# ESP32-P4 register map
Vendor: ESPRESSIF SYSTEMS (SHANGHAI) CO., LTD.; Series: ESP32 P-Series; File version: 3
CPU: RV32IMAFC r0p0, little endian, no MPU, FPU, 0 interrupt priority bits
Address unit: 32 bits
Registers are 32-bit, read-write, reset 0x0 unless marked. A register's access mark holds for its fields unless they carry their own. Offsets are from the block's base; [hi:lo] are bit positions; {n}, {i} and the like mark numbered series; <NAME> marks a mode.

## ISP (part 1 of 2) — ISP Peripheral
Base 0x500A1000
0x00 VER_DATE reset 0x20210608 — version control register
  [31:0] VER_DATA — csv version
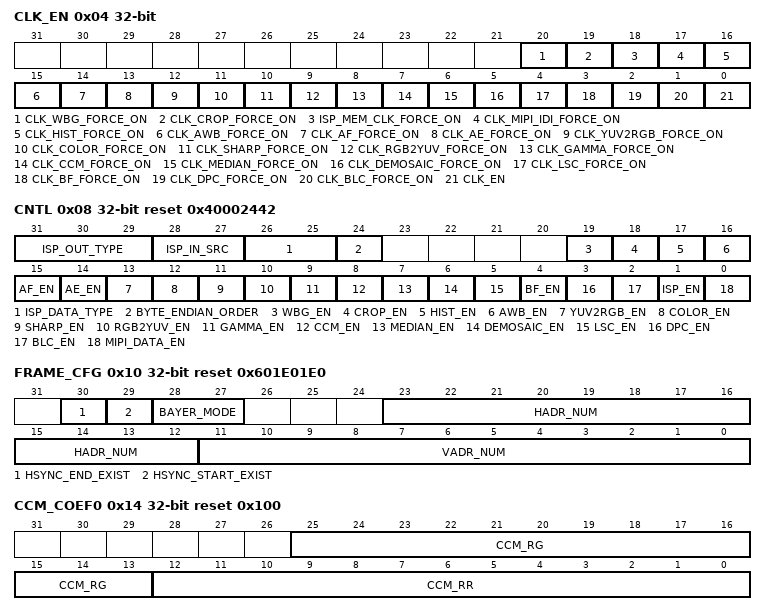
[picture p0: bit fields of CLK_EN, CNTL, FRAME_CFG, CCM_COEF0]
0x04 CLK_EN — isp clk control register
  [20] CLK_WBG_FORCE_ON — this bit configures the clk force on of wbg. 0: disable, 1: enable
  [19] CLK_CROP_FORCE_ON — this bit configures the clk force on of crop. 0: disable, 1: enable
  [18] ISP_MEM_CLK_FORCE_ON — this bit configures the clk force on of all isp memory. 0: disable, 1: enable
  [17] CLK_MIPI_IDI_FORCE_ON — this bit configures the clk force on of mipi idi input. 0: disable, 1: enable
  [16] CLK_HIST_FORCE_ON — this bit configures the clk force on of hist. 0: disable, 1: enable
  [15] CLK_AWB_FORCE_ON — this bit configures the clk force on of awb. 0: disable, 1: enable
  [14] CLK_AF_FORCE_ON — this bit configures the clk force on of af. 0: disable, 1: enable
  [13] CLK_AE_FORCE_ON — this bit configures the clk force on of ae. 0: disable, 1: enable
  [12] CLK_YUV2RGB_FORCE_ON — this bit configures the clk force on of yuv2rgb. 0: disable, 1: enable
  [11] CLK_COLOR_FORCE_ON — this bit configures the clk force on of color. 0: disable, 1: enable
  [10] CLK_SHARP_FORCE_ON — this bit configures the clk force on of sharp. 0: disable, 1: enable
  [9] CLK_RGB2YUV_FORCE_ON — this bit configures the clk force on of rgb2yuv. 0: disable, 1: enable
  [8] CLK_GAMMA_FORCE_ON — this bit configures the clk force on of gamma. 0: disable, 1: enable
  [7] CLK_CCM_FORCE_ON — this bit configures the clk force on of ccm. 0: disable, 1: enable
  [6] CLK_MEDIAN_FORCE_ON — this bit configures the clk force on of median. 0: disable, 1: enable
  [5] CLK_DEMOSAIC_FORCE_ON — this bit configures the clk force on of demosaic. 0: disable, 1: enable
  [4] CLK_LSC_FORCE_ON — this bit configures the clk force on of lsc. 0: disable, 1: enable
  [3] CLK_BF_FORCE_ON — this bit configures the clk force on of bf. 0: disable, 1: enable
  [2] CLK_DPC_FORCE_ON — this bit configures the clk force on of dpc. 0: disable, 1: enable
  [1] CLK_BLC_FORCE_ON — this bit configures the clk force on of blc. 0: disable, 1: enable
  [0] CLK_EN — this bit configures the clk force on of isp reg. 0: disable, 1: enable
0x08 CNTL reset 0x40002442 — isp module enable control register
  [31:29] ISP_OUT_TYPE — this field configures pixel output type, 0: RAW8 1: YUV422 2: RGB888 3: YUV420 4: RGB565
  [28:27] ISP_IN_SRC — this field configures input data source, 0:CSI HOST 1:CAM 2:DMA
  [26:25] ISP_DATA_TYPE — this field configures input data type, 0:RAW8 1:RAW10 2:RAW12
  [24] BYTE_ENDIAN_ORDER — select input idi data byte_endian_order when isp is bypass, 0: csi_data[31:0], 1: {[7:0], [15:8], [23:16], [31:24]}
  [19] WBG_EN — this bit configures wbg enable. 0: disable, 1: enable
  [18] CROP_EN — this bit configures crop enable. 0: disable, 1: enable
  [17] HIST_EN — this bit configures hist enable. 0: disable, 1: enable
  [16] AWB_EN — this bit configures awb enable. 0: disable, 1: enable
  [15] AF_EN — this bit configures af enable. 0: disable, 1: enable
  [14] AE_EN — this bit configures ae enable. 0: disable, 1: enable
  [13] YUV2RGB_EN — this bit configures yuv2rgb enable. 0: disable, 1: enable
  [12] COLOR_EN — this bit configures color enable. 0: disable, 1: enable
  [11] SHARP_EN — this bit configures sharp enable. 0: disable, 1: enable
  [10] RGB2YUV_EN — this bit configures rgb2yuv enable. 0: disable, 1: enable
  [9] GAMMA_EN — this bit configures gamma enable. 0: disable, 1: enable
  [8] CCM_EN — this bit configures ccm enable. 0: disable, 1: enable
  [7] MEDIAN_EN — this bit configures median enable. 0: disable, 1: enable
  [6] DEMOSAIC_EN — this bit configures demosaic enable. 0: disable, 1: enable
  [5] LSC_EN — this bit configures lsc enable. 0: disable, 1: enable
  [4] BF_EN — this bit configures bf enable. 0: disable, 1: enable
  [3] DPC_EN — this bit configures dpc enable. 0: disable, 1: enable
  [2] BLC_EN — this bit configures blc enable. 0: disable, 1: enable
  [1] ISP_EN — this bit configures isp global enable. 0: disable, 1: enable
  [0] MIPI_DATA_EN — this bit configures mipi input data enable. 0: disable, 1: enable
0x0C HSYNC_CNT reset 0x7 — header hsync interval control register
  [7:0] HSYNC_CNT — this field configures the number of clock before hsync and after vsync and line_end when decodes pix data from idi to isp
0x10 FRAME_CFG reset 0x601E01E0 — frame control parameter register
  [30] HSYNC_END_EXIST — this bit configures the line start packet exist or not. 0: not exist, 1: exist
  [29] HSYNC_START_EXIST — this bit configures the line end packet exist or not. 0: not exist, 1: exist
  [28:27] BAYER_MODE — this field configures the bayer mode of input pixel. 00 : BG/GR 01 : GB/RG 10 : GR/BG 11 : RG/GB
  [23:12] HADR_NUM — this field configures input image size in x-direction, image line number - 1
  [11:0] VADR_NUM — this field configures input image size in y-direction, image row number - 1
0x14 CCM_COEF0 reset 0x100 — ccm coef register 0
  [25:13] CCM_RG — this field configures the color correction matrix coefficient
  [12:0] CCM_RR — this field configures the color correction matrix coefficient
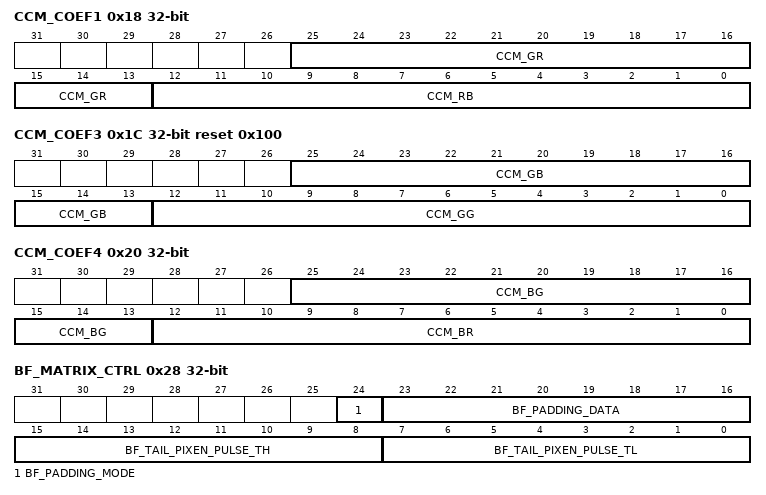
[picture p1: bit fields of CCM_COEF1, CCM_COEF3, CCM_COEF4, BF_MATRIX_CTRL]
0x18 CCM_COEF1 — ccm coef register 1
  [25:13] CCM_GR — this field configures the color correction matrix coefficient
  [12:0] CCM_RB — this field configures the color correction matrix coefficient
0x1C CCM_COEF3 reset 0x100 — ccm coef register 3
  [25:13] CCM_GB — this field configures the color correction matrix coefficient
  [12:0] CCM_GG — this field configures the color correction matrix coefficient
0x20 CCM_COEF4 — ccm coef register 4
  [25:13] CCM_BG — this field configures the color correction matrix coefficient
  [12:0] CCM_BR — this field configures the color correction matrix coefficient
0x24 CCM_COEF5 reset 0x100 — ccm coef register 5
  [12:0] CCM_BB — this field configures the color correction matrix coefficient
0x28 BF_MATRIX_CTRL — bf pix2matrix ctrl
  [24] BF_PADDING_MODE — this bit configures the padding mode of bf matrix. 0: use pixel in image to do padding 1: use reg_padding_data to do padding
  [23:16] BF_PADDING_DATA — this field configures bf matrix padding data
  [15:8] BF_TAIL_PIXEN_PULSE_TH — matrix tail pixen high level threshold, must < hnum-1, only reg_bf_tail_pixen_pulse_th!=0 and reg_bf_tail_pixen_pulse_tl!=0 and reg_bf_tail_pixen_pulse_th < reg_bf_tail_pixen_pulse_tl will enable tail pulse function
  [7:0] BF_TAIL_PIXEN_PULSE_TL — matrix tail pixen low level threshold, should not to large to prevent expanding to next frame, only reg_bf_tail_pixen_pulse_th!=0 and reg_bf_tail_pixen_pulse_tl!=0 and reg_bf_tail_pixen_pulse_th < reg_bf_tail_pixen_pulse_tl will enable tail pulse function
0x2C BF_SIGMA reset 0x2 — bf denoising level control register
  [5:0] SIGMA — this field configures the bayer denoising level, valid data from 2 to 20
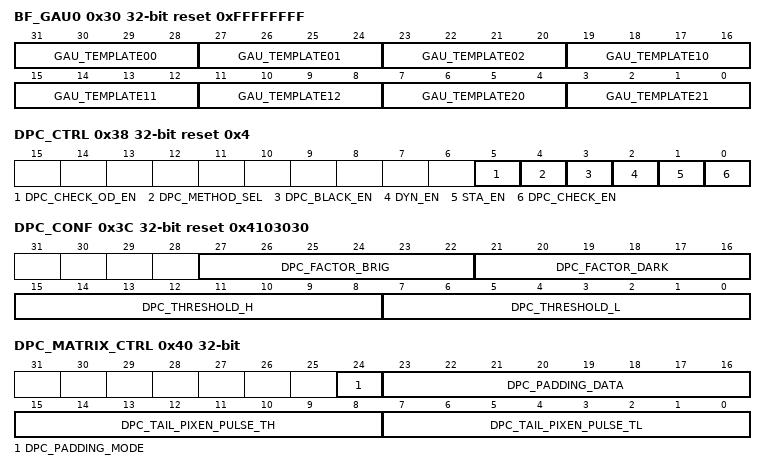
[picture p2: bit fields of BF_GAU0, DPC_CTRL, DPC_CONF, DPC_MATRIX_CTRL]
0x30 BF_GAU0 reset 0xFFFFFFFF — bf gau template register 0
  [31:28] GAU_TEMPLATE00 — this field configures index 00 of gausian template
  [27:24] GAU_TEMPLATE01 — this field configures index 01 of gausian template
  [23:20] GAU_TEMPLATE02 — this field configures index 02 of gausian template
  [19:16] GAU_TEMPLATE10 — this field configures index 10 of gausian template
  [15:12] GAU_TEMPLATE11 — this field configures index 11 of gausian template
  [11:8] GAU_TEMPLATE12 — this field configures index 12 of gausian template
  [7:4] GAU_TEMPLATE20 — this field configures index 20 of gausian template
  [3:0] GAU_TEMPLATE21 — this field configures index 21 of gausian template
0x34 BF_GAU1 reset 0xF — bf gau template register 1
  [3:0] GAU_TEMPLATE22 — this field configures index 22 of gausian template
0x38 DPC_CTRL reset 0x4 — DPC mode control register
  [5] DPC_CHECK_OD_EN — this bit configures output pixel data when in check mode or not. 0: no data output, 1: data output
  [4] DPC_METHOD_SEL — this bit configures dyn dpc method select. 0: simple method, 1: hard method
  [3] DPC_BLACK_EN — this bit configures input image type select when in check mode, 0: white img, 1: black img
  [2] DYN_EN — this bit configures the dyn dpc enable. 0: disable, 1: enable
  [1] STA_EN — this bit configures the sta dpc enable. 0: disable, 1: enable
  [0] DPC_CHECK_EN — this bit configures the check mode enable. 0: disable, 1: enable
0x3C DPC_CONF reset 0x4103030 — DPC parameter config register
  [27:22] DPC_FACTOR_BRIG — this field configures the dynamic correction method 1 bright factor
  [21:16] DPC_FACTOR_DARK — this field configures the dynamic correction method 1 dark factor
  [15:8] DPC_THRESHOLD_H — this bit configures the threshold to detect white img in check mode, or the high threshold(use 8 bit 0~255) in dyn method 0, or the high threshold factor (use 5 bit 10000-> 16/16, 00001->1/16, 0/16~16/16) in dyn method 1
  [7:0] DPC_THRESHOLD_L — this bit configures the threshold to detect black img in check mode, or the low threshold(use 8 bit 0~255) in dyn method 0, or the low threshold factor (use 5 bit 10000-> 16/16, 00001->1/16, 0/16~16/16) in dyn method 1
0x40 DPC_MATRIX_CTRL — dpc pix2matrix ctrl
  [24] DPC_PADDING_MODE — this bit configures the padding mode of dpc matrix. 0: use pixel in image to do padding 1: use reg_padding_data to do padding
  [23:16] DPC_PADDING_DATA — this field configures dpc matrix padding data
  [15:8] DPC_TAIL_PIXEN_PULSE_TH — matrix tail pixen high level threshold, must < hnum-1, only reg_dpc_tail_pixen_pulse_th!=0 and reg_dpc_tail_pixen_pulse_tl!=0 and reg_dpc_tail_pixen_pulse_th < reg_dpc_tail_pixen_pulse_tl will enable tail pulse function
  [7:0] DPC_TAIL_PIXEN_PULSE_TL — matrix tail pixen low level threshold, should not to large to prevent expanding to next frame, only reg_dpc_tail_pixen_pulse_th!=0 and reg_dpc_tail_pixen_pulse_tl!=0 and reg_dpc_tail_pixen_pulse_th < reg_dpc_tail_pixen_pulse_tl will enable tail pulse function
0x44 DPC_DEADPIX_CNT ro — DPC dead-pix number register
  [9:0] DPC_DEADPIX_CNT — this field represents the dead pixel count
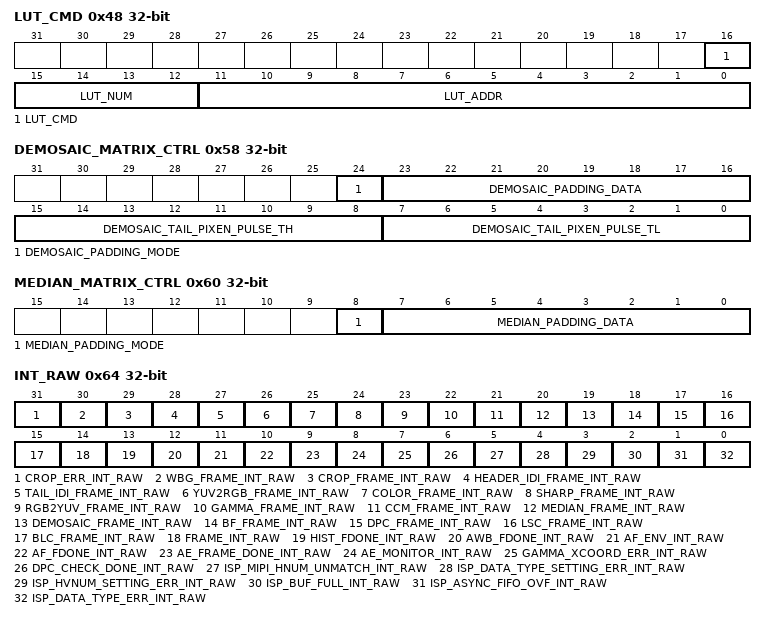
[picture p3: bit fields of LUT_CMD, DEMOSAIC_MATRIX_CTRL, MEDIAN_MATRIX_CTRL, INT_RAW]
0x48 LUT_CMD wo — LUT command register
  [16] LUT_CMD — this bit configures the access event of lut. 0:rd 1: wr
  [15:12] LUT_NUM — this field configures the lut selection. 0000:LSC LUT. 0001:DPC LUT. 0010:AWB LUT
  [11:0] LUT_ADDR — this field configures the lut access addr, when select lsc lut, [11:10]:00 sel gb_b lut, 01 sel r_gr lut
0x4C LUT_WDATA — LUT write data register
  [31:0] LUT_WDATA — this field configures the write data of lut. please initial ISP_LUT_WDATA before write ISP_LUT_CMD register
0x50 LUT_RDATA ro — LUT read data register
  [31:0] LUT_RDATA — this field represents the read data of lut. read ISP_LUT_RDATA after write ISP_LUT_CMD register
0x54 LSC_TABLESIZE reset 0x1F — LSC point in x-direction
  [4:0] LSC_XTABLESIZE — this field configures lsc table size in x-direction
0x58 DEMOSAIC_MATRIX_CTRL — demosaic pix2matrix ctrl
  [24] DEMOSAIC_PADDING_MODE — this bit configures the padding mode of demosaic matrix. 0: use pixel in image to do padding 1: use reg_padding_data to do padding
  [23:16] DEMOSAIC_PADDING_DATA — this field configures demosaic matrix padding data
  [15:8] DEMOSAIC_TAIL_PIXEN_PULSE_TH — matrix tail pixen high level threshold, must < hnum-1, only reg_demosaic_tail_pixen_pulse_th!=0 and reg_demosaic_tail_pixen_pulse_tl!=0 and reg_demosaic_tail_pixen_pulse_th < reg_demosaic_tail_pixen_pulse_tl will enable tail pulse function
  [7:0] DEMOSAIC_TAIL_PIXEN_PULSE_TL — matrix tail pixen low level threshold, should not to large to prevent expanding to next frame, only reg_demosaic_tail_pixen_pulse_th!=0 and reg_demosaic_tail_pixen_pulse_tl!=0 and reg_demosaic_tail_pixen_pulse_th < reg_demosaic_tail_pixen_pulse_tl will enable tail pulse function
0x5C DEMOSAIC_GRAD_RATIO reset 0x10 — demosaic gradient select ratio
  [5:0] DEMOSAIC_GRAD_RATIO — this field configures demosaic gradient select ratio
0x60 MEDIAN_MATRIX_CTRL — median pix2matrix ctrl
  [8] MEDIAN_PADDING_MODE — this bit configures the padding mode of median matrix. 0: use pixel in image to do padding 1: use reg_padding_data to do padding
  [7:0] MEDIAN_PADDING_DATA — this field configures median matrix padding data
0x64 INT_RAW ro — raw interrupt register
  [31] CROP_ERR_INT_RAW — the raw interrupt status of crop error
  [30] WBG_FRAME_INT_RAW — the raw interrupt status of wbg frame done
  [29] CROP_FRAME_INT_RAW — the raw interrupt status of crop frame done
  [28] HEADER_IDI_FRAME_INT_RAW — the raw interrupt status of real input frame end of isp_input
  [27] TAIL_IDI_FRAME_INT_RAW — the raw interrupt status of isp_tail idi frame_end
  [26] YUV2RGB_FRAME_INT_RAW — the raw interrupt status of yuv2rgb frame done
  [25] COLOR_FRAME_INT_RAW — the raw interrupt status of color frame done
  [24] SHARP_FRAME_INT_RAW — the raw interrupt status of sharp frame done
  [23] RGB2YUV_FRAME_INT_RAW — the raw interrupt status of rgb2yuv frame done
  [22] GAMMA_FRAME_INT_RAW — the raw interrupt status of gamma frame done
  [21] CCM_FRAME_INT_RAW — the raw interrupt status of ccm frame done
  [20] MEDIAN_FRAME_INT_RAW — the raw interrupt status of median frame done
  [19] DEMOSAIC_FRAME_INT_RAW — the raw interrupt status of demosaic frame done
  [18] BF_FRAME_INT_RAW — the raw interrupt status of bf frame done
  [17] DPC_FRAME_INT_RAW — the raw interrupt status of dpc frame done
  [16] LSC_FRAME_INT_RAW — the raw interrupt status of lsc frame done
  [15] BLC_FRAME_INT_RAW — the raw interrupt status of blc frame done
  [14] FRAME_INT_RAW — the raw interrupt status of isp frame end
  [13] HIST_FDONE_INT_RAW — the raw interrupt status of histogram. send a int pulse when statistic of one frame histogram done
  [12] AWB_FDONE_INT_RAW — the raw interrupt status of awb. send a int pulse when statistic of one awb frame done
  [11] AF_ENV_INT_RAW — the raw interrupt status of af monitor. send a int pulse when env_det function enabled and environment changes detected
  [10] AF_FDONE_INT_RAW — the raw interrupt status of af statistic. when auto_update enable, each frame done will send one int pulse when manual_update, each time when write 1 to reg_manual_update will send a int pulse when next frame done
  [9] AE_FRAME_DONE_INT_RAW — the raw interrupt status of ae.
  [8] AE_MONITOR_INT_RAW — the raw interrupt status of ae monitor
  [7] GAMMA_XCOORD_ERR_INT_RAW — the raw interrupt status of gamma setting error. it report the sum of the lengths represented by reg_gamma_x00~x0F isn't equal to 256
  [6] DPC_CHECK_DONE_INT_RAW — the raw interrupt status of dpc check done
  [5] ISP_MIPI_HNUM_UNMATCH_INT_RAW — the raw interrupt status of hnum setting unmatch with mipi input
  [4] ISP_DATA_TYPE_SETTING_ERR_INT_RAW — the raw interrupt status of setting invalid reg_data_type
  [3] ISP_HVNUM_SETTING_ERR_INT_RAW — the raw interrupt status of hnum and vnum setting format error
  [2] ISP_BUF_FULL_INT_RAW — the raw interrupt status of isp input buffer full
  [1] ISP_ASYNC_FIFO_OVF_INT_RAW — the raw interrupt status of isp input fifo overflow
  [0] ISP_DATA_TYPE_ERR_INT_RAW — the raw interrupt status of input data type error. isp only support RGB bayer data type, other type will report type_err_int
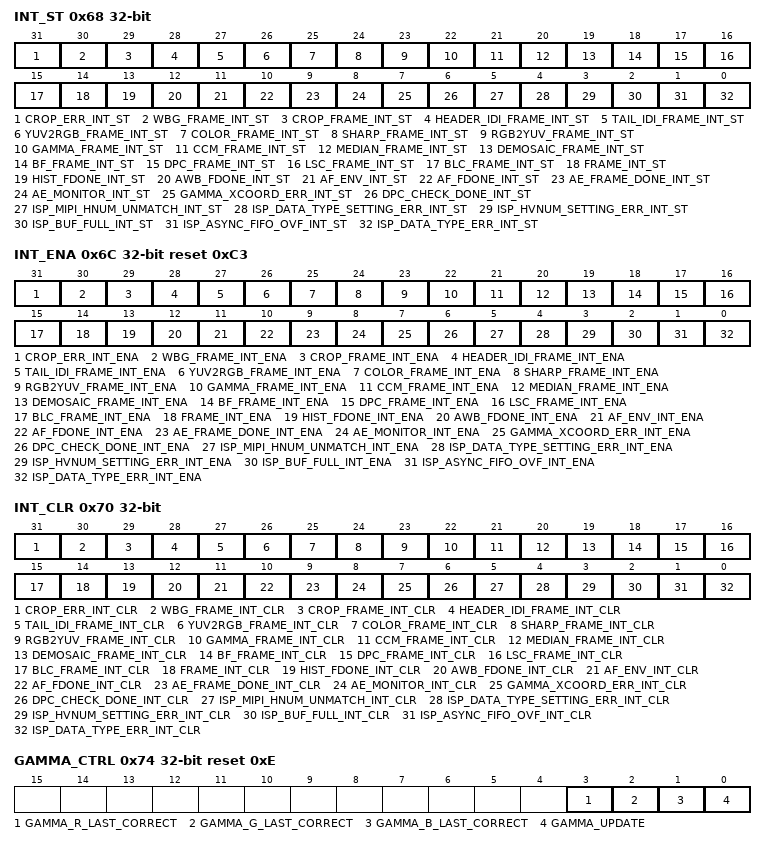
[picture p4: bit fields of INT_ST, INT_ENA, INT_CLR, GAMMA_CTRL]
0x68 INT_ST ro — masked interrupt register
  [31] CROP_ERR_INT_ST — the masked interrupt status of crop error
  [30] WBG_FRAME_INT_ST — the masked interrupt status of wbg frame done
  [29] CROP_FRAME_INT_ST — the masked interrupt status of crop frame done
  [28] HEADER_IDI_FRAME_INT_ST — the masked interrupt status of real input frame end of isp_input
  [27] TAIL_IDI_FRAME_INT_ST — the masked interrupt status of isp_tail idi frame_end
  [26] YUV2RGB_FRAME_INT_ST — the masked interrupt status of yuv2rgb frame done
  [25] COLOR_FRAME_INT_ST — the masked interrupt status of color frame done
  [24] SHARP_FRAME_INT_ST — the masked interrupt status of sharp frame done
  [23] RGB2YUV_FRAME_INT_ST — the masked interrupt status of rgb2yuv frame done
  [22] GAMMA_FRAME_INT_ST — the masked interrupt status of gamma frame done
  [21] CCM_FRAME_INT_ST — the masked interrupt status of ccm frame done
  [20] MEDIAN_FRAME_INT_ST — the masked interrupt status of median frame done
  [19] DEMOSAIC_FRAME_INT_ST — the masked interrupt status of demosaic frame done
  [18] BF_FRAME_INT_ST — the masked interrupt status of bf frame done
  [17] DPC_FRAME_INT_ST — the masked interrupt status of dpc frame done
  [16] LSC_FRAME_INT_ST — the masked interrupt status of lsc frame done
  [15] BLC_FRAME_INT_ST — the masked interrupt status of blc frame done
  [14] FRAME_INT_ST — the masked interrupt status of isp frame end
  [13] HIST_FDONE_INT_ST — the masked interrupt status of histogram
  [12] AWB_FDONE_INT_ST — the masked interrupt status of awb
  [11] AF_ENV_INT_ST — the masked interrupt status of af monitor
  [10] AF_FDONE_INT_ST — the masked interrupt status of af statistic
  [9] AE_FRAME_DONE_INT_ST — the masked interrupt status of ae
  [8] AE_MONITOR_INT_ST — the masked interrupt status of ae monitor
  [7] GAMMA_XCOORD_ERR_INT_ST — the masked interrupt status of gamma setting error
  [6] DPC_CHECK_DONE_INT_ST — the masked interrupt status of dpc check done
  [5] ISP_MIPI_HNUM_UNMATCH_INT_ST — the masked interrupt status of hnum setting unmatch with mipi input
  [4] ISP_DATA_TYPE_SETTING_ERR_INT_ST — the masked interrupt status of setting invalid reg_data_type
  [3] ISP_HVNUM_SETTING_ERR_INT_ST — the masked interrupt status of hnum and vnum setting format error
  [2] ISP_BUF_FULL_INT_ST — the masked interrupt status of isp input buffer full
  [1] ISP_ASYNC_FIFO_OVF_INT_ST — the masked interrupt status of isp input fifo overflow
  [0] ISP_DATA_TYPE_ERR_INT_ST — the masked interrupt status of input data type error
0x6C INT_ENA reset 0xC3 — interrupt enable register
  [31] CROP_ERR_INT_ENA — write 1 to enable crop error
  [30] WBG_FRAME_INT_ENA — write 1 to enable wbg frame done
  [29] CROP_FRAME_INT_ENA — write 1 to enable crop frame done
  [28] HEADER_IDI_FRAME_INT_ENA — write 1 to enable real input frame end of isp_input
  [27] TAIL_IDI_FRAME_INT_ENA — write 1 to enable isp_tail idi frame_end
  [26] YUV2RGB_FRAME_INT_ENA — write 1 to enable yuv2rgb frame done
  [25] COLOR_FRAME_INT_ENA — write 1 to enable color frame done
  [24] SHARP_FRAME_INT_ENA — write 1 to enable sharp frame done
  [23] RGB2YUV_FRAME_INT_ENA — write 1 to enable rgb2yuv frame done
  [22] GAMMA_FRAME_INT_ENA — write 1 to enable gamma frame done
  [21] CCM_FRAME_INT_ENA — write 1 to enable ccm frame done
  [20] MEDIAN_FRAME_INT_ENA — write 1 to enable median frame done
  [19] DEMOSAIC_FRAME_INT_ENA — write 1 to enable demosaic frame done
  [18] BF_FRAME_INT_ENA — write 1 to enable bf frame done
  [17] DPC_FRAME_INT_ENA — write 1 to enable dpc frame done
  [16] LSC_FRAME_INT_ENA — write 1 to enable lsc frame done
  [15] BLC_FRAME_INT_ENA — write 1 to enable blc frame done
  [14] FRAME_INT_ENA — write 1 to enable isp frame end
  [13] HIST_FDONE_INT_ENA — write 1 to enable histogram
  [12] AWB_FDONE_INT_ENA — write 1 to enable awb
  [11] AF_ENV_INT_ENA — write 1 to enable af monitor
  [10] AF_FDONE_INT_ENA — write 1 to enable af statistic
  [9] AE_FRAME_DONE_INT_ENA — write 1 to enable ae
  [8] AE_MONITOR_INT_ENA — write 1 to enable ae monitor
  [7] GAMMA_XCOORD_ERR_INT_ENA — write 1 to enable gamma setting error
  [6] DPC_CHECK_DONE_INT_ENA — write 1 to enable dpc check done
  [5] ISP_MIPI_HNUM_UNMATCH_INT_ENA — write 1 to enable hnum setting unmatch with mipi input
  [4] ISP_DATA_TYPE_SETTING_ERR_INT_ENA — write 1 to enable setting invalid reg_data_type
  [3] ISP_HVNUM_SETTING_ERR_INT_ENA — write 1 to enable hnum and vnum setting format error
  [2] ISP_BUF_FULL_INT_ENA — write 1 to enable isp input buffer full
  [1] ISP_ASYNC_FIFO_OVF_INT_ENA — write 1 to enable isp input fifo overflow
  [0] ISP_DATA_TYPE_ERR_INT_ENA — write 1 to enable input data type error
0x70 INT_CLR wo — interrupt clear register
  [31] CROP_ERR_INT_CLR — write 1 to clear crop error
  [30] WBG_FRAME_INT_CLR — write 1 to clear wbg frame done
  [29] CROP_FRAME_INT_CLR — write 1 to clear crop frame done
  [28] HEADER_IDI_FRAME_INT_CLR — write 1 to clear real input frame end of isp_input
  [27] TAIL_IDI_FRAME_INT_CLR — write 1 to clear isp_tail idi frame_end
  [26] YUV2RGB_FRAME_INT_CLR — write 1 to clear yuv2rgb frame done
  [25] COLOR_FRAME_INT_CLR — write 1 to clear color frame done
  [24] SHARP_FRAME_INT_CLR — write 1 to clear sharp frame done
  [23] RGB2YUV_FRAME_INT_CLR — write 1 to clear rgb2yuv frame done
  [22] GAMMA_FRAME_INT_CLR — write 1 to clear gamma frame done
  [21] CCM_FRAME_INT_CLR — write 1 to clear ccm frame done
  [20] MEDIAN_FRAME_INT_CLR — write 1 to clear median frame done
  [19] DEMOSAIC_FRAME_INT_CLR — write 1 to clear demosaic frame done
  [18] BF_FRAME_INT_CLR — write 1 to clear bf frame done
  [17] DPC_FRAME_INT_CLR — write 1 to clear dpc frame done
  [16] LSC_FRAME_INT_CLR — write 1 to clear lsc frame done
  [15] BLC_FRAME_INT_CLR — write 1 to clear blc frame done
  [14] FRAME_INT_CLR — write 1 to clear isp frame end
  [13] HIST_FDONE_INT_CLR — write 1 to clear histogram
  [12] AWB_FDONE_INT_CLR — write 1 to clear awb
  [11] AF_ENV_INT_CLR — write 1 to clear af monitor
  [10] AF_FDONE_INT_CLR — write 1 to clear af statistic
  [9] AE_FRAME_DONE_INT_CLR — write 1 to clear ae
  [8] AE_MONITOR_INT_CLR — write 1 to clear ae monitor
  [7] GAMMA_XCOORD_ERR_INT_CLR — write 1 to clear gamma setting error
  [6] DPC_CHECK_DONE_INT_CLR — write 1 to clear dpc check done
  [5] ISP_MIPI_HNUM_UNMATCH_INT_CLR — write 1 to clear hnum setting unmatch with mipi input
  [4] ISP_DATA_TYPE_SETTING_ERR_INT_CLR — write 1 to clear setting invalid reg_data_type
  [3] ISP_HVNUM_SETTING_ERR_INT_CLR — write 1 to clear hnum and vnum setting format error
  [2] ISP_BUF_FULL_INT_CLR — write 1 to clear isp input buffer full
  [1] ISP_ASYNC_FIFO_OVF_INT_CLR — write 1 to clear isp input fifo overflow
  [0] ISP_DATA_TYPE_ERR_INT_CLR — write 1 to clear input data type error
0x74 GAMMA_CTRL reset 0xE — gamma control register
  [3] GAMMA_R_LAST_CORRECT — this bit configures enable of last r segment correcction. 0: disable, 1: enable
  [2] GAMMA_G_LAST_CORRECT — this bit configures enable of last g segment correcction. 0: disable, 1: enable
  [1] GAMMA_B_LAST_CORRECT — this bit configures enable of last b segment correcction. 0: disable, 1: enable
  [0] GAMMA_UPDATE — Indicates that gamma register configuration is complete
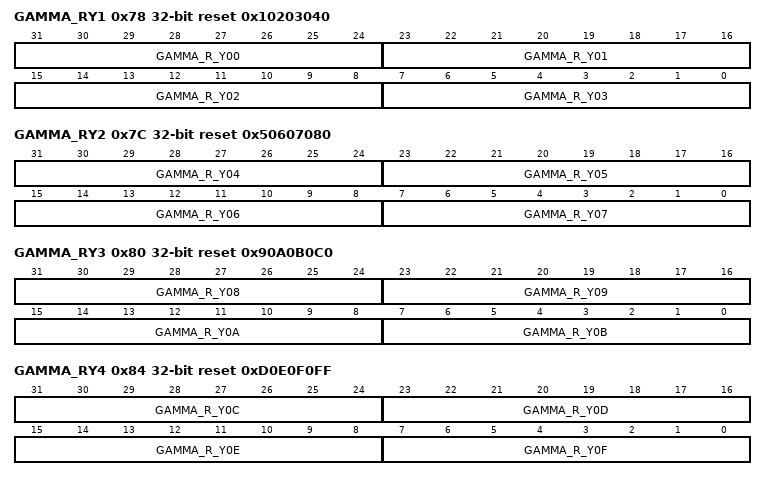
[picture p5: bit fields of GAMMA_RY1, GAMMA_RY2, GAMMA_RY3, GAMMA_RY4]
0x78 GAMMA_RY1 reset 0x10203040 — point of Y-axis of r channel gamma curve register 1
  [31-8n:24-8n] GAMMA_R_Y{n:02} (n=0..3) — this field configures the point {n} of Y-axis of r channel gamma curve
0x7C GAMMA_RY2 reset 0x50607080 — point of Y-axis of r channel gamma curve register 2
  [63-8n:56-8n] GAMMA_R_Y{n:02} (n=4..7) — this field configures the point {n} of Y-axis of r channel gamma curve
0x80 GAMMA_RY3 reset 0x90A0B0C0 — point of Y-axis of r channel gamma curve register 3
  [31:24] GAMMA_R_Y08 — this field configures the point 8 of Y-axis of r channel gamma curve
  [23:16] GAMMA_R_Y09 — this field configures the point 9 of Y-axis of r channel gamma curve
  [15:8] GAMMA_R_Y0A — this field configures the point 10 of Y-axis of r channel gamma curve
  [7:0] GAMMA_R_Y0B — this field configures the point 11 of Y-axis of r channel gamma curve
0x84 GAMMA_RY4 reset 0xD0E0F0FF — point of Y-axis of r channel gamma curve register 4
  [31:24] GAMMA_R_Y0C — this field configures the point 12 of Y-axis of r channel gamma curve
  [23:16] GAMMA_R_Y0D — this field configures the point 13 of Y-axis of r channel gamma curve
  [15:8] GAMMA_R_Y0E — this field configures the point 14 of Y-axis of r channel gamma curve
  [7:0] GAMMA_R_Y0F — this field configures the point 15 of Y-axis of r channel gamma curve
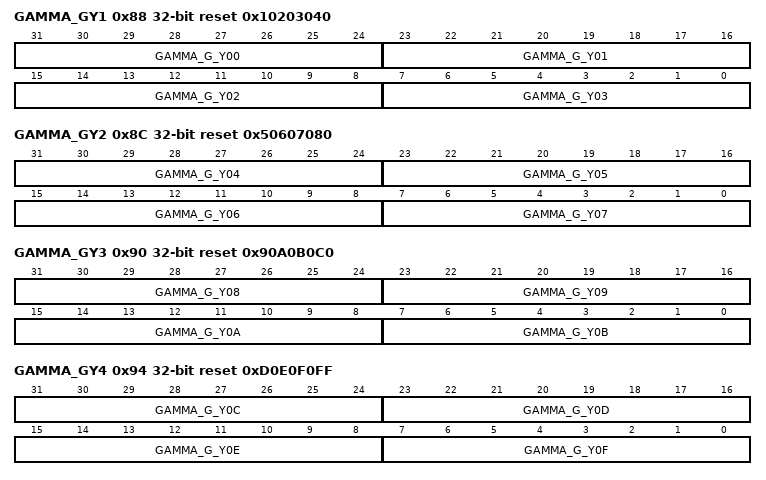
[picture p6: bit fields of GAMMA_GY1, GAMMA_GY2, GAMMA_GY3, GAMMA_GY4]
0x88 GAMMA_GY1 reset 0x10203040 — point of Y-axis of g channel gamma curve register 1
  [31-8n:24-8n] GAMMA_G_Y{n:02} (n=0..3) — this field configures the point {n} of Y-axis of g channel gamma curve
0x8C GAMMA_GY2 reset 0x50607080 — point of Y-axis of g channel gamma curve register 2
  [63-8n:56-8n] GAMMA_G_Y{n:02} (n=4..7) — this field configures the point {n} of Y-axis of g channel gamma curve
0x90 GAMMA_GY3 reset 0x90A0B0C0 — point of Y-axis of g channel gamma curve register 3
  [31:24] GAMMA_G_Y08 — this field configures the point 8 of Y-axis of g channel gamma curve
  [23:16] GAMMA_G_Y09 — this field configures the point 9 of Y-axis of g channel gamma curve
  [15:8] GAMMA_G_Y0A — this field configures the point 10 of Y-axis of g channel gamma curve
  [7:0] GAMMA_G_Y0B — this field configures the point 11 of Y-axis of g channel gamma curve
0x94 GAMMA_GY4 reset 0xD0E0F0FF — point of Y-axis of g channel gamma curve register 4
  [31:24] GAMMA_G_Y0C — this field configures the point 12 of Y-axis of g channel gamma curve
  [23:16] GAMMA_G_Y0D — this field configures the point 13 of Y-axis of g channel gamma curve
  [15:8] GAMMA_G_Y0E — this field configures the point 14 of Y-axis of g channel gamma curve
  [7:0] GAMMA_G_Y0F — this field configures the point 15 of Y-axis of g channel gamma curve
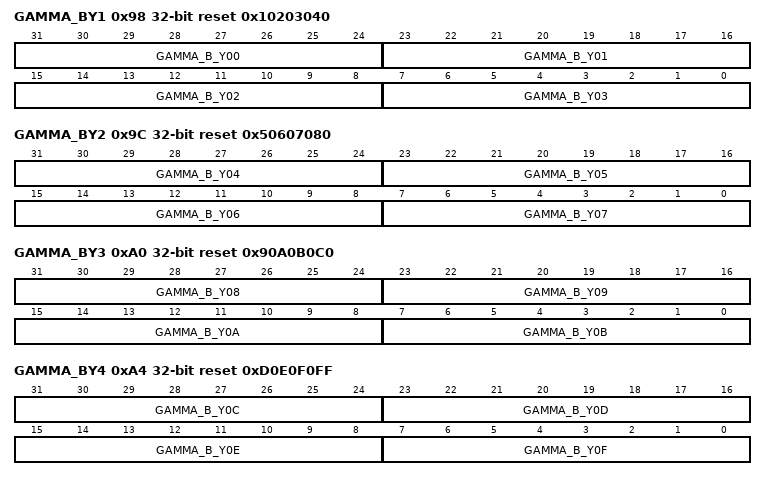
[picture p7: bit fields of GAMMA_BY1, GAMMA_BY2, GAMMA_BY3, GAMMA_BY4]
0x98 GAMMA_BY1 reset 0x10203040 — point of Y-axis of b channel gamma curve register 1
  [31-8n:24-8n] GAMMA_B_Y{n:02} (n=0..3) — this field configures the point {n} of Y-axis of b channel gamma curve
0x9C GAMMA_BY2 reset 0x50607080 — point of Y-axis of b channel gamma curve register 2
  [63-8n:56-8n] GAMMA_B_Y{n:02} (n=4..7) — this field configures the point {n} of Y-axis of b channel gamma curve
0xA0 GAMMA_BY3 reset 0x90A0B0C0 — point of Y-axis of b channel gamma curve register 3
  [31:24] GAMMA_B_Y08 — this field configures the point 8 of Y-axis of b channel gamma curve
  [23:16] GAMMA_B_Y09 — this field configures the point 9 of Y-axis of b channel gamma curve
  [15:8] GAMMA_B_Y0A — this field configures the point 10 of Y-axis of b channel gamma curve
  [7:0] GAMMA_B_Y0B — this field configures the point 11 of Y-axis of b channel gamma curve
0xA4 GAMMA_BY4 reset 0xD0E0F0FF — point of Y-axis of b channel gamma curve register 4
  [31:24] GAMMA_B_Y0C — this field configures the point 12 of Y-axis of b channel gamma curve
  [23:16] GAMMA_B_Y0D — this field configures the point 13 of Y-axis of b channel gamma curve
  [15:8] GAMMA_B_Y0E — this field configures the point 14 of Y-axis of b channel gamma curve
  [7:0] GAMMA_B_Y0F — this field configures the point 15 of Y-axis of b channel gamma curve
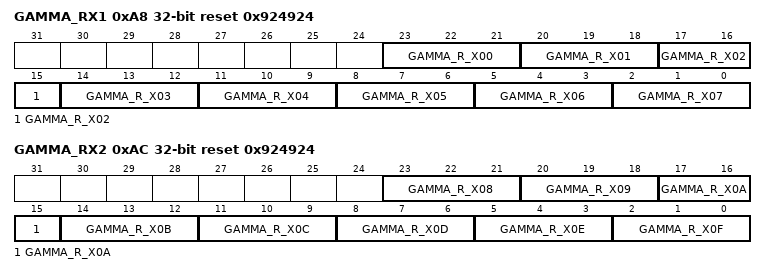
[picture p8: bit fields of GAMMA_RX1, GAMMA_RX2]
0xA8 GAMMA_RX1 reset 0x924924 — point of X-axis of r channel gamma curve register 1
  [23-3n:21-3n] GAMMA_R_X{n:02} (n=0..7) — this field configures the point {n} of X-axis of r channel gamma curve, it represents the power of the distance from the previous point
0xAC GAMMA_RX2 reset 0x924924 — point of X-axis of r channel gamma curve register 2
  [23:21] GAMMA_R_X08 — this field configures the point 8 of X-axis of r channel gamma curve, it represents the power of the distance from the previous point
  [20:18] GAMMA_R_X09 — this field configures the point 9 of X-axis of r channel gamma curve, it represents the power of the distance from the previous point
  [17:15] GAMMA_R_X0A — this field configures the point 10 of X-axis of r channel gamma curve, it represents the power of the distance from the previous point
  [14:12] GAMMA_R_X0B — this field configures the point 11 of X-axis of r channel gamma curve, it represents the power of the distance from the previous point
  [11:9] GAMMA_R_X0C — this field configures the point 12 of X-axis of r channel gamma curve, it represents the power of the distance from the previous point
  [8:6] GAMMA_R_X0D — this field configures the point 13 of X-axis of r channel gamma curve, it represents the power of the distance from the previous point
  [5:3] GAMMA_R_X0E — this field configures the point 14 of X-axis of r channel gamma curve, it represents the power of the distance from the previous point
  [2:0] GAMMA_R_X0F — this field configures the point 15 of X-axis of r channel gamma curve, it represents the power of the distance from the previous point
